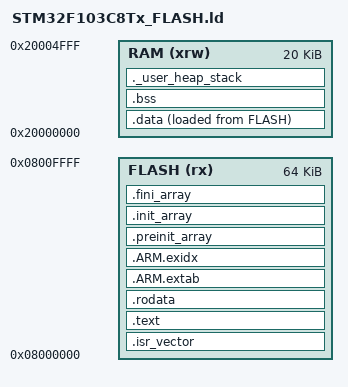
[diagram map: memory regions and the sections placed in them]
/* STM32F103C8: 64 KiB Flash, 20 KiB SRAM, no bootloader offset. */
ENTRY(Reset_Handler)

MEMORY
{
    FLASH (rx)  : ORIGIN = 0x08000000, LENGTH = 64K
    RAM   (xrw) : ORIGIN = 0x20000000, LENGTH = 20K
}

_estack = ORIGIN(RAM) + LENGTH(RAM);
/* newlib's floating-point formatting needs heap and stack space. */
_Min_Heap_Size = 0x1000;
_Min_Stack_Size = 0x800;
__StackTop = _estack;
__StackLimit = _estack - _Min_Stack_Size;

SECTIONS
{
    .isr_vector :
    {
        . = ALIGN(4);
        KEEP(*(.isr_vector))
        . = ALIGN(4);
    } > FLASH

    .text :
    {
        . = ALIGN(4);
        *(.text .text.*)
        KEEP(*(.init))
        KEEP(*(.fini))
        . = ALIGN(4);
    } > FLASH

    .rodata :
    {
        . = ALIGN(4);
        *(.rodata .rodata.*)
        . = ALIGN(4);
    } > FLASH

    .ARM.extab : { *(.ARM.extab* .gnu.linkonce.armextab.*) } > FLASH
    .ARM.exidx :
    {
        __exidx_start = .;
        *(.ARM.exidx* .gnu.linkonce.armexidx.*)
        __exidx_end = .;
    } > FLASH

    .preinit_array :
    {
        . = ALIGN(4);
        PROVIDE_HIDDEN(__preinit_array_start = .);
        KEEP(*(.preinit_array*))
        PROVIDE_HIDDEN(__preinit_array_end = .);
    } > FLASH

    .init_array :
    {
        . = ALIGN(4);
        PROVIDE_HIDDEN(__init_array_start = .);
        KEEP(*(SORT(.init_array.*)))
        KEEP(*(.init_array))
        PROVIDE_HIDDEN(__init_array_end = .);
    } > FLASH

    .fini_array :
    {
        . = ALIGN(4);
        PROVIDE_HIDDEN(__fini_array_start = .);
        KEEP(*(SORT(.fini_array.*)))
        KEEP(*(.fini_array))
        PROVIDE_HIDDEN(__fini_array_end = .);
    } > FLASH

    .data :
    {
        . = ALIGN(4);
        _sdata = .;
        *(.data .data.*)
        *(.RamFunc .RamFunc.*)
        . = ALIGN(4);
        _edata = .;
    } > RAM AT > FLASH
    _sidata = LOADADDR(.data);

    .bss (NOLOAD) :
    {
        . = ALIGN(4);
        _sbss = .;
        *(.bss .bss.*)
        *(COMMON)
        . = ALIGN(4);
        _ebss = .;
    } > RAM

    ._user_heap_stack (NOLOAD) :
    {
        . = ALIGN(8);
        __HeapBase = .;
        _end = .;
        PROVIDE(end = .);
        . += _Min_Heap_Size;
        __HeapLimit = .;
        . += _Min_Stack_Size;
        . = ALIGN(8);
    } > RAM

    .ARM.attributes 0 : { *(.ARM.attributes) }
}

ASSERT(__HeapLimit <= __StackLimit, "RAM overflow: heap overlaps reserved stack")
